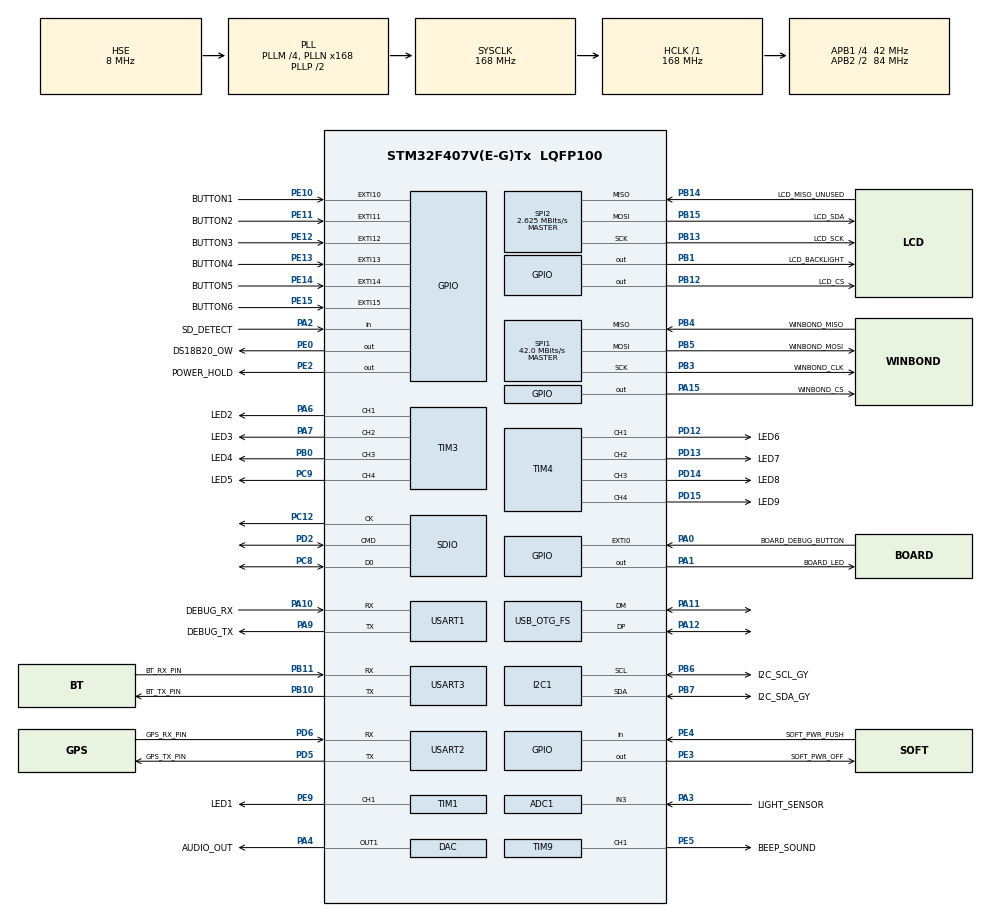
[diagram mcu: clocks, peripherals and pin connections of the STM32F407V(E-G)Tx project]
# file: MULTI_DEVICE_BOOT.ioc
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ADC1.Channel-0\#ChannelRegularConversion=ADC_CHANNEL_3
ADC1.NbrOfConversionFlag=1
ADC1.Rank-0\#ChannelRegularConversion=1
ADC1.SamplingTime-0\#ChannelRegularConversion=ADC_SAMPLETIME_3CYCLES
ADC1.master=1
DAC.DAC_Trigger=DAC_TRIGGER_T6_TRGO
Dma.DAC1.0.Direction=DMA_MEMORY_TO_PERIPH
Dma.DAC1.0.FIFOMode=DMA_FIFOMODE_DISABLE
Dma.DAC1.0.Instance=DMA1_Stream5
Dma.DAC1.0.MemDataAlignment=DMA_MDATAALIGN_HALFWORD
Dma.DAC1.0.MemInc=DMA_MINC_ENABLE
Dma.DAC1.0.Mode=DMA_CIRCULAR
Dma.DAC1.0.PeriphDataAlignment=DMA_PDATAALIGN_HALFWORD
Dma.DAC1.0.PeriphInc=DMA_PINC_DISABLE
Dma.DAC1.0.Priority=DMA_PRIORITY_HIGH
Dma.Request0=DAC1
FATFS.BSP.number=1
FATFS0.BSP.STBoard=false
FATFS0.BSP.api=Unknown
FATFS0.BSP.instance=PA2
FATFS0.BSP.ip=GPIO
FATFS0.BSP.mode=Input
FATFS0.BSP.name=Detect_SDIO
FATFS0.BSP.solution=PA2
I2C1.I2C_Mode=I2C_Fast
Mcu.Family=STM32F4
Mcu.Name=STM32F407V(E-G)Tx
Mcu.Package=LQFP100
NVIC.DMA1_Stream5_IRQn=true\:0\:0\:false\:false\:true\:false\:true\:true
NVIC.EXTI0_IRQn=true\:0\:0\:false\:false\:true\:true\:true\:true
NVIC.EXTI15_10_IRQn=true\:0\:0\:false\:false\:true\:true\:true\:true
NVIC.PriorityGroup=NVIC_PRIORITYGROUP_4
NVIC.TIM7_IRQn=true\:0\:0\:false\:false\:true\:true\:true\:true
NVIC.USART1_IRQn=true\:0\:0\:false\:false\:true\:true\:true\:true
NVIC.USART2_IRQn=true\:0\:0\:false\:false\:true\:true\:true\:true
NVIC.USART3_IRQn=true\:0\:0\:false\:false\:true\:true\:true\:true
PA0-WKUP.GPIO_Label=BOARD_DEBUG_BUTTON
PA0-WKUP.GPIO_PuPd=GPIO_NOPULL
PA0-WKUP.Signal=GPXTI0
PA1.GPIO_Label=BOARD_LED
PA1.Signal=GPIO_Output
PA10.GPIO_Label=DEBUG_RX
PA10.Mode=Asynchronous
PA10.Signal=USART1_RX
PA11.Mode=Device_Only
PA11.Signal=USB_OTG_FS_DM
PA12.Mode=Device_Only
PA12.Signal=USB_OTG_FS_DP
PA15.GPIO_Label=WINBOND_CS
PA15.GPIO_PuPd=GPIO_PULLUP
PA15.PinState=GPIO_PIN_SET
PA15.Signal=GPIO_Output
PA2.GPIO_Label=SD_DETECT
PA2.Signal=GPIO_Input
PA3.GPIO_Label=LIGHT_SENSOR
PA3.Signal=ADCx_IN3
PA4.GPIO_Label=AUDIO_OUT
PA4.Signal=COMP_DAC1_group
PA6.GPIO_Label=LED2
PA6.Signal=S_TIM3_CH1
PA7.GPIO_Label=LED3
PA7.Signal=S_TIM3_CH2
PA9.GPIO_Label=DEBUG_TX
PA9.GPIO_Speed=GPIO_SPEED_FREQ_VERY_HIGH
PA9.Mode=Asynchronous
PA9.Signal=USART1_TX
PB0.GPIO_Label=LED4
PB0.Signal=S_TIM3_CH3
PB1.GPIO_Label=LCD_BACKLIGHT
PB1.Signal=GPIO_Output
PB10.GPIO_Label=BT_TX_PIN
PB10.Mode=Asynchronous
PB10.Signal=USART3_TX
PB11.GPIO_Label=BT_RX_PIN
PB11.Mode=Asynchronous
PB11.Signal=USART3_RX
PB12.GPIO_Label=LCD_CS
PB12.GPIO_PuPd=GPIO_PULLUP
PB12.PinState=GPIO_PIN_SET
PB12.Signal=GPIO_Output
PB13.GPIO_Label=LCD_SCK
PB13.Mode=Full_Duplex_Master
PB13.Signal=SPI2_SCK
PB14.GPIO_Label=LCD_MISO_UNUSED
PB14.Mode=Full_Duplex_Master
PB14.Signal=SPI2_MISO
PB15.GPIO_Label=LCD_SDA
PB15.Mode=Full_Duplex_Master
PB15.Signal=SPI2_MOSI
PB3.GPIO_Label=WINBOND_CLK
PB3.Mode=Full_Duplex_Master
PB3.Signal=SPI1_SCK
PB4.GPIO_Label=WINBOND_MISO
PB4.Mode=Full_Duplex_Master
PB4.Signal=SPI1_MISO
PB5.GPIO_Label=WINBOND_MOSI
PB5.Mode=Full_Duplex_Master
PB5.Signal=SPI1_MOSI
PB6.GPIO_Label=I2C_SCL_GY
PB6.Mode=I2C
PB6.Signal=I2C1_SCL
PB7.GPIO_Label=I2C_SDA_GY
PB7.Mode=I2C
PB7.Signal=I2C1_SDA
PC12.Mode=SD_1_bit
PC12.Signal=SDIO_CK
PC14-OSC32_IN.Mode=LSE-External-Oscillator
PC14-OSC32_IN.Signal=RCC_OSC32_IN
PC15-OSC32_OUT.Mode=LSE-External-Oscillator
PC15-OSC32_OUT.Signal=RCC_OSC32_OUT
PC8.Mode=SD_1_bit
PC8.Signal=SDIO_D0
PC9.GPIO_Label=LED5
PC9.Signal=S_TIM3_CH4
PD12.GPIO_Label=LED6
PD12.Signal=S_TIM4_CH1
PD13.GPIO_Label=LED7
PD13.Signal=S_TIM4_CH2
PD14.GPIO_Label=LED8
PD14.Signal=S_TIM4_CH3
PD15.GPIO_Label=LED9
PD15.Signal=S_TIM4_CH4
PD2.Mode=SD_1_bit
PD2.Signal=SDIO_CMD
PD5.GPIO_Label=GPS_TX_PIN
PD5.Mode=Asynchronous
PD5.Signal=USART2_TX
PD6.GPIO_Label=GPS_RX_PIN
PD6.Mode=Asynchronous
PD6.Signal=USART2_RX
PE0.GPIO_Label=DS18B20_OW
PE0.GPIO_ModeDefaultOutputPP=GPIO_MODE_OUTPUT_OD
PE0.GPIO_PuPd=GPIO_NOPULL
PE0.Signal=GPIO_Output
PE10.GPIO_Label=BUTTON1
PE10.GPIO_ModeDefaultEXTI=GPIO_MODE_IT_RISING_FALLING
PE10.GPIO_PuPd=GPIO_PULLUP
PE10.Signal=GPXTI10
PE11.GPIO_Label=BUTTON2
PE11.GPIO_ModeDefaultEXTI=GPIO_MODE_IT_RISING_FALLING
PE11.GPIO_PuPd=GPIO_PULLUP
PE11.Signal=GPXTI11
PE12.GPIO_Label=BUTTON3
PE12.GPIO_ModeDefaultEXTI=GPIO_MODE_IT_RISING_FALLING
PE12.GPIO_PuPd=GPIO_PULLUP
PE12.Signal=GPXTI12
PE13.GPIO_Label=BUTTON4
PE13.GPIO_ModeDefaultEXTI=GPIO_MODE_IT_RISING_FALLING
PE13.GPIO_PuPd=GPIO_PULLUP
PE13.Signal=GPXTI13
PE14.GPIO_Label=BUTTON5
PE14.GPIO_ModeDefaultEXTI=GPIO_MODE_IT_RISING_FALLING
PE14.GPIO_PuPd=GPIO_PULLUP
PE14.Signal=GPXTI14
PE15.GPIO_Label=BUTTON6
PE15.GPIO_ModeDefaultEXTI=GPIO_MODE_IT_RISING_FALLING
PE15.GPIO_PuPd=GPIO_PULLUP
PE15.Signal=GPXTI15
PE2.GPIO_Label=POWER_HOLD
PE2.Signal=GPIO_Output
PE3.GPIO_Label=SOFT_PWR_OFF
PE3.Signal=GPIO_Output
PE4.GPIO_Label=SOFT_PWR_PUSH
PE4.Signal=GPIO_Input
PE5.GPIO_Label=BEEP_SOUND
PE5.Signal=S_TIM9_CH1
PE9.GPIO_Label=LED1
PE9.Signal=S_TIM1_CH1
PH0-OSC_IN.Mode=HSE-External-Oscillator
PH0-OSC_IN.Signal=RCC_OSC_IN
PH1-OSC_OUT.Mode=HSE-External-Oscillator
PH1-OSC_OUT.Signal=RCC_OSC_OUT
ProjectManager.HeapSize=0x200
ProjectManager.StackSize=0x400
ProjectManager.TargetToolchain=STM32CubeIDE
RCC.48MHZClocksFreq_Value=48000000
RCC.AHBFreq_Value=168000000
RCC.APB1CLKDivider=RCC_HCLK_DIV4
RCC.APB1Freq_Value=42000000
RCC.APB1TimFreq_Value=84000000
RCC.APB2CLKDivider=RCC_HCLK_DIV2
RCC.APB2Freq_Value=84000000
RCC.APB2TimFreq_Value=168000000
RCC.CortexFreq_Value=168000000
RCC.HCLKFreq_Value=168000000
RCC.HSE_VALUE=8000000
RCC.HSI_VALUE=16000000
RCC.PLLM=4
RCC.PLLN=168
RCC.PLLQ=7
RCC.RCC_RTC_Clock_Source=RCC_RTCCLKSOURCE_LSE
RCC.RCC_RTC_Clock_SourceVirtual=RCC_RTCCLKSOURCE_LSE
RCC.SYSCLKFreq_VALUE=168000000
RCC.SYSCLKSource=RCC_SYSCLKSOURCE_PLLCLK
RCC.VCOOutputFreq_Value=336000000
SH.ADCx_IN3.0=ADC1_IN3,IN3
SH.COMP_DAC1_group.0=DAC_OUT1,DAC_OUT1
SH.S_TIM1_CH1.0=TIM1_CH1,PWM Generation1 CH1
SH.S_TIM3_CH1.0=TIM3_CH1,PWM Generation1 CH1
SH.S_TIM3_CH2.0=TIM3_CH2,PWM Generation2 CH2
SH.S_TIM3_CH3.0=TIM3_CH3,PWM Generation3 CH3
SH.S_TIM3_CH4.0=TIM3_CH4,PWM Generation4 CH4
SH.S_TIM4_CH1.0=TIM4_CH1,PWM Generation1 CH1
SH.S_TIM4_CH2.0=TIM4_CH2,PWM Generation2 CH2
SH.S_TIM4_CH3.0=TIM4_CH3,PWM Generation3 CH3
SH.S_TIM4_CH4.0=TIM4_CH4,PWM Generation4 CH4
SH.S_TIM9_CH1.0=TIM9_CH1,PWM Generation1 CH1
SPI1.CalculateBaudRate=42.0 MBits/s
SPI1.Direction=SPI_DIRECTION_2LINES
SPI1.Mode=SPI_MODE_MASTER
SPI1.VirtualType=VM_MASTER
SPI2.BaudRatePrescaler=SPI_BAUDRATEPRESCALER_16
SPI2.CalculateBaudRate=2.625 MBits/s
SPI2.Direction=SPI_DIRECTION_2LINES
SPI2.Mode=SPI_MODE_MASTER
SPI2.VirtualType=VM_MASTER
TIM1.Channel-PWM\ Generation1\ CH1=TIM_CHANNEL_1
TIM3.Channel-PWM\ Generation1\ CH1=TIM_CHANNEL_1
TIM3.Channel-PWM\ Generation2\ CH2=TIM_CHANNEL_2
TIM3.Channel-PWM\ Generation3\ CH3=TIM_CHANNEL_3
TIM3.Channel-PWM\ Generation4\ CH4=TIM_CHANNEL_4
TIM4.Channel-PWM\ Generation1\ CH1=TIM_CHANNEL_1
TIM4.Channel-PWM\ Generation2\ CH2=TIM_CHANNEL_2
TIM4.Channel-PWM\ Generation3\ CH3=TIM_CHANNEL_3
TIM4.Channel-PWM\ Generation4\ CH4=TIM_CHANNEL_4
TIM6.Period=3499
TIM7.Period=499
TIM7.Prescaler=8399
TIM9.Channel-PWM\ Generation1\ CH1=TIM_CHANNEL_1
USART1.VirtualMode=VM_ASYNC
USART2.VirtualMode=VM_ASYNC
USART3.VirtualMode=VM_ASYNC
USB_OTG_FS.VirtualMode=Device_Only
VP_ADC1_Vbat_Input.Mode=IN-Vbat
VP_ADC1_Vref_Input.Mode=IN-Vrefint
VP_FATFS_VS_SDIO.Mode=SDIO
VP_RTC_VS_RTC_Activate.Mode=RTC_Enabled
VP_TIM6_VS_ClockSourceINT.Mode=Enable_Timer
VP_TIM7_VS_ClockSourceINT.Mode=Enable_Timer
board=custom

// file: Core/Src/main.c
/* USER CODE BEGIN Header */
/**
  ******************************************************************************
  * @file           : main.c
  * @brief          : resident F/W Update Mode Boot project entry
  ******************************************************************************
  *
  *  이 파일은 CubeMX가 생성한 bootloader 프로젝트의 Core/Src/main.c 를
  *  그대로 대체해서 사용하는 용도다.
  *
  *  설계 포인트
  *  - 이 프로젝트는 반드시 0x08000000 부트 영역에 링크된다.
  *  - Main App 은 0x08020000 부터 별도 프로젝트로 링크된다.
  *  - Reset 직후에는 항상 이 main() 으로 들어온다.
  *  - 여기서는 부트에 필요한 최소 peripheral만 초기화한다.
  *  - 실제 진입 판단 / UI / SD package 설치는 Firmware 폴더 쪽으로 넘긴다.
  *
  ******************************************************************************
  */
/* USER CODE END Header */
#include "main.h"
#include "adc.h"
#include "dac.h"
#include "dma.h"
#include "fatfs.h"
#include "i2c.h"
#include "rtc.h"
#include "sdio.h"
#include "spi.h"
#include "tim.h"
#include "usart.h"
#include "usb_otg.h"
#include "gpio.h"

/* USER CODE BEGIN Includes */
#include "APP_FAULT.h"
#include "FW_BootMain.h"

#include "FW_Power.h"
/* USER CODE END Includes */

void SystemClock_Config(void);

int main(void)
{

  /* MCU Configuration--------------------------------------------------------*/

  /* Reset of all peripherals, Initializes the Flash interface and the Systick. */
  HAL_Init();

  /* Configure the system clock */
  SystemClock_Config();

  /* Initialize all configured peripherals */
  MX_GPIO_Init();
  MX_DMA_Init();
  MX_SDIO_SD_Init();
  MX_SPI1_Init();
  MX_SPI2_Init();
  MX_USB_OTG_FS_PCD_Init();
  MX_I2C1_Init();
  MX_USART1_UART_Init();
  MX_USART2_UART_Init();
  MX_USART3_UART_Init();
  MX_FATFS_Init();
  MX_TIM1_Init();
  MX_TIM3_Init();
  MX_TIM4_Init();
  MX_TIM9_Init();
  MX_ADC1_Init();
  MX_RTC_Init();
  MX_TIM7_Init();
  MX_DAC_Init();
  MX_TIM6_Init();
  /* USER CODE BEGIN 2 */
  FW_BOOT_Run();
  /* USER CODE END 2 */

  /* Infinite loop */
  while (1)
  {

  }
}

void SystemClock_Config(void)
{
  RCC_OscInitTypeDef RCC_OscInitStruct = {0};
  RCC_ClkInitTypeDef RCC_ClkInitStruct = {0};

  /** Configure the main internal regulator output voltage
  */
  __HAL_RCC_PWR_CLK_ENABLE();
  __HAL_PWR_VOLTAGESCALING_CONFIG(PWR_REGULATOR_VOLTAGE_SCALE1);

  /** Initializes the RCC Oscillators according to the specified parameters
  * in the RCC_OscInitTypeDef structure.
  */
  RCC_OscInitStruct.OscillatorType = RCC_OSCILLATORTYPE_HSE|RCC_OSCILLATORTYPE_LSE;
  RCC_OscInitStruct.HSEState = RCC_HSE_ON;
  RCC_OscInitStruct.LSEState = RCC_LSE_ON;
  RCC_OscInitStruct.PLL.PLLState = RCC_PLL_ON;
  RCC_OscInitStruct.PLL.PLLSource = RCC_PLLSOURCE_HSE;
  RCC_OscInitStruct.PLL.PLLM = 4;
  RCC_OscInitStruct.PLL.PLLN = 168;
  RCC_OscInitStruct.PLL.PLLP = RCC_PLLP_DIV2;
  RCC_OscInitStruct.PLL.PLLQ = 7;
  if (HAL_RCC_OscConfig(&RCC_OscInitStruct) != HAL_OK)
  {
    Error_Handler();
  }

  /** Initializes the CPU, AHB and APB buses clocks
  */
  RCC_ClkInitStruct.ClockType = RCC_CLOCKTYPE_HCLK|RCC_CLOCKTYPE_SYSCLK
                              |RCC_CLOCKTYPE_PCLK1|RCC_CLOCKTYPE_PCLK2;
  RCC_ClkInitStruct.SYSCLKSource = RCC_SYSCLKSOURCE_PLLCLK;
  RCC_ClkInitStruct.AHBCLKDivider = RCC_SYSCLK_DIV1;
  RCC_ClkInitStruct.APB1CLKDivider = RCC_HCLK_DIV4;
  RCC_ClkInitStruct.APB2CLKDivider = RCC_HCLK_DIV2;

  if (HAL_RCC_ClockConfig(&RCC_ClkInitStruct, FLASH_LATENCY_5) != HAL_OK)
  {
    Error_Handler();
  }
}

void Error_Handler(void)
{
  __disable_irq();
  while (1)
  {
  }
}
